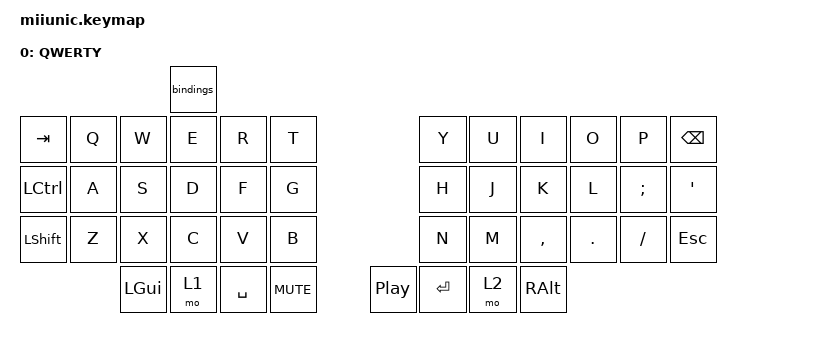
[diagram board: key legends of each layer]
#include <behaviors.dtsi>
#include <dt-bindings/zmk/keys.h>

/ {
    keymap {
        compatible = "zmk,keymap";

        qwerty_layer {
            display-name = "QWERTY";
            bindings = <
// -----------------------------------------------------------------------------------------
// |  TAB |  Q  |  W  |  E  |  R  |  T  |               |  Y  |  U   |  I  |  O  |  P  | BSPC |
// | CTRL |  A  |  S  |  D  |  F  |  G  |               |  H  |  J   |  K  |  L  |  ;  |  '   |
// | SHFT |  Z  |  X  |  C  |  V  |  B  |               |  N  |  M   |  ,  |  .  |  /  | ESC  |
//                    | GUI | LWR | SPC | MUTE |   | PP | ENT | RSE  | ALT |
                        bindings = <
   &kp TAB   &kp Q &kp W &kp E &kp R &kp T                       &kp Y &kp U  &kp I     &kp O   &kp P    &kp BSPC
   &kp LCTRL &kp A &kp S &kp D &kp F &kp G                       &kp H &kp J  &kp K     &kp L   &kp SEMI &kp SQT
   &kp LSHFT &kp Z &kp X &kp C &kp V &kp B                       &kp N &kp M  &kp COMMA &kp DOT &kp FSLH &kp ESC
                  &kp LGUI &mo 1 &kp SPACE &kp C_MUTE   &kp C_PP &kp RET &mo 2 &kp RALT
            >;
            sensor-bindings = <&inc_dec_kp C_VOL_DN C_VOL_UP &inc_dec_kp PG_DN PG_UP>;
        };
    };
};
